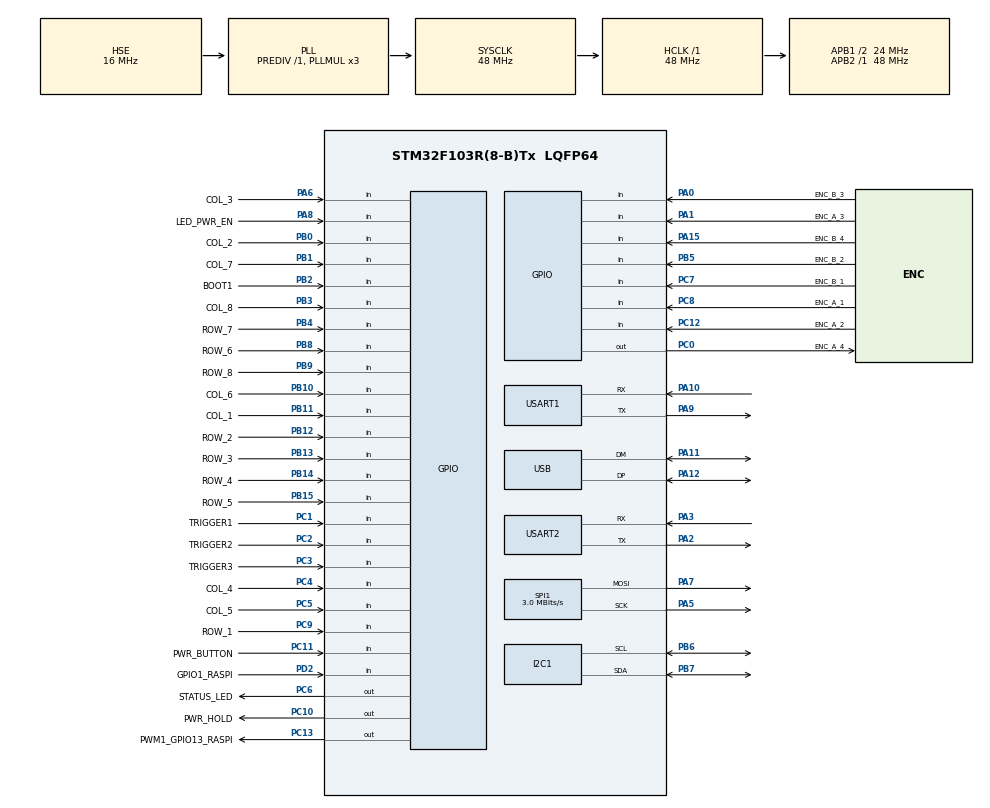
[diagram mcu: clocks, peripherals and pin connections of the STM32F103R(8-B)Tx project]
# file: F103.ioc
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Dma.Request0=SPI1_TX
Dma.SPI1_TX.0.Direction=DMA_MEMORY_TO_PERIPH
Dma.SPI1_TX.0.Instance=DMA1_Channel3
Dma.SPI1_TX.0.MemDataAlignment=DMA_MDATAALIGN_BYTE
Dma.SPI1_TX.0.MemInc=DMA_MINC_ENABLE
Dma.SPI1_TX.0.Mode=DMA_NORMAL
Dma.SPI1_TX.0.PeriphDataAlignment=DMA_PDATAALIGN_BYTE
Dma.SPI1_TX.0.PeriphInc=DMA_PINC_DISABLE
Dma.SPI1_TX.0.Priority=DMA_PRIORITY_LOW
Mcu.Family=STM32F1
Mcu.Name=STM32F103R(8-B)Tx
Mcu.Package=LQFP64
NVIC.DMA1_Channel3_IRQn=true\:0\:0\:false\:false\:true\:false\:true
NVIC.PriorityGroup=NVIC_PRIORITYGROUP_4
PA0-WKUP.GPIO_Label=ENC_B_3
PA0-WKUP.Signal=GPIO_Input
PA1.GPIO_Label=ENC_A_3
PA1.Signal=GPIO_Input
PA10.Mode=Asynchronous
PA10.Signal=USART1_RX
PA11.Mode=Device
PA11.Signal=USB_DM
PA12.Mode=Device
PA12.Signal=USB_DP
PA13.Mode=Serial_Wire
PA13.Signal=SYS_JTMS-SWDIO
PA14.Mode=Serial_Wire
PA14.Signal=SYS_JTCK-SWCLK
PA15.GPIO_Label=ENC_B_4
PA15.Signal=GPIO_Input
PA2.Mode=Asynchronous
PA2.Signal=USART2_TX
PA3.Mode=Asynchronous
PA3.Signal=USART2_RX
PA5.Mode=TX_Only_Simplex_Unidirect_Master
PA5.Signal=SPI1_SCK
PA6.GPIO_Label=COL_3
PA6.Signal=GPIO_Input
PA7.Mode=TX_Only_Simplex_Unidirect_Master
PA7.Signal=SPI1_MOSI
PA8.GPIO_Label=LED_PWR_EN
PA8.Signal=GPIO_Input
PA9.Mode=Asynchronous
PA9.Signal=USART1_TX
PB0.GPIO_Label=COL_2
PB0.Signal=GPIO_Input
PB1.GPIO_Label=COL_7
PB1.Signal=GPIO_Input
PB10.GPIO_Label=COL_6
PB10.Signal=GPIO_Input
PB11.GPIO_Label=COL_1
PB11.Signal=GPIO_Input
PB12.GPIO_Label=ROW_2
PB12.Signal=GPIO_Input
PB13.GPIO_Label=ROW_3
PB13.Signal=GPIO_Input
PB14.GPIO_Label=ROW_4
PB14.Signal=GPIO_Input
PB15.GPIO_Label=ROW_5
PB15.Signal=GPIO_Input
PB2.GPIO_Label=BOOT1
PB2.Signal=GPIO_Input
PB3.GPIO_Label=COL_8
PB3.Signal=GPIO_Input
PB4.GPIO_Label=ROW_7
PB4.Signal=GPIO_Input
PB5.GPIO_Label=ENC_B_2
PB5.Signal=GPIO_Input
PB6.Mode=I2C
PB6.Signal=I2C1_SCL
PB7.Mode=I2C
PB7.Signal=I2C1_SDA
PB8.GPIO_Label=ROW_6
PB8.Signal=GPIO_Input
PB9.GPIO_Label=ROW_8
PB9.Signal=GPIO_Input
PC0.GPIO_Label=ENC_A_4
PC0.Signal=GPIO_Output
PC1.GPIO_Label=TRIGGER1
PC1.Signal=GPIO_Input
PC10.GPIO_Label=PWR_HOLD
PC10.Signal=GPIO_Output
PC11.GPIO_Label=PWR_BUTTON
PC11.Signal=GPIO_Input
PC12.GPIO_Label=ENC_A_2
PC12.Signal=GPIO_Input
PC13-TAMPER-RTC.GPIO_Label=PWM1_GPIO13_RASPI
PC13-TAMPER-RTC.Signal=GPIO_Output
PC14-OSC32_IN.Mode=LSE-External-Oscillator
PC14-OSC32_IN.Signal=RCC_OSC32_IN
PC15-OSC32_OUT.Mode=LSE-External-Oscillator
PC15-OSC32_OUT.Signal=RCC_OSC32_OUT
PC2.GPIO_Label=TRIGGER2
PC2.Signal=GPIO_Input
PC3.GPIO_Label=TRIGGER3
PC3.Signal=GPIO_Input
PC4.GPIO_Label=COL_4
PC4.Signal=GPIO_Input
PC5.GPIO_Label=COL_5
PC5.Signal=GPIO_Input
PC6.GPIO_Label=STATUS_LED
PC6.Signal=GPIO_Output
PC7.GPIO_Label=ENC_B_1
PC7.Signal=GPIO_Input
PC8.GPIO_Label=ENC_A_1
PC8.Signal=GPIO_Input
PC9.GPIO_Label=ROW_1
PC9.Signal=GPIO_Input
PD0-OSC_IN.Mode=HSE-External-Oscillator
PD0-OSC_IN.Signal=RCC_OSC_IN
PD1-OSC_OUT.Mode=HSE-External-Oscillator
PD1-OSC_OUT.Signal=RCC_OSC_OUT
PD2.GPIO_Label=GPIO1_RASPI
PD2.Signal=GPIO_Input
ProjectManager.HeapSize=0x200
ProjectManager.StackSize=0x400
ProjectManager.TargetToolchain=Makefile
RCC.AHBFreq_Value=48000000
RCC.APB1CLKDivider=RCC_HCLK_DIV2
RCC.APB1Freq_Value=24000000
RCC.APB1TimFreq_Value=48000000
RCC.APB2Freq_Value=48000000
RCC.APB2TimFreq_Value=48000000
RCC.HCLKFreq_Value=48000000
RCC.HSE_VALUE=16000000
RCC.PLLMUL=RCC_PLL_MUL3
RCC.PLLSourceVirtual=RCC_PLLSOURCE_HSE
RCC.RTCClockSelection=RCC_RTCCLKSOURCE_LSE
RCC.SYSCLKFreq_VALUE=48000000
RCC.SYSCLKSource=RCC_SYSCLKSOURCE_PLLCLK
RCC.USBFreq_Value=48000000
SPI1.BaudRatePrescaler=SPI_BAUDRATEPRESCALER_16
SPI1.CalculateBaudRate=3.0 MBits/s
SPI1.Direction=SPI_DIRECTION_2LINES
SPI1.Mode=SPI_MODE_MASTER
SPI1.VirtualType=VM_MASTER
USART1.VirtualMode=VM_ASYNC
USART2.VirtualMode=VM_ASYNC
VP_RTC_VS_RTC_Activate.Mode=RTC_Enabled
board=custom

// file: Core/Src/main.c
/* USER CODE BEGIN Header */
/**
  ******************************************************************************
  * @file           : main.c
  * @brief          : Main program body
  ******************************************************************************
  * @attention
  *
  * <h2><center>&copy; Copyright (c) 2021 STMicroelectronics.
  * All rights reserved.</center></h2>
  *
  * This software component is licensed by ST under BSD 3-Clause license,
  * the "License"; You may not use this file except in compliance with the
  * License. You may obtain a copy of the License at:
  *                        opensource.org/licenses/BSD-3-Clause
  *
  ******************************************************************************
  */
/* USER CODE END Header */
#include "main.h"
#include "dma.h"
#include "i2c.h"
#include "rtc.h"
#include "spi.h"
#include "usart.h"
#include "usb.h"
#include "gpio.h"

/* USER CODE BEGIN Includes */
#include "../../Otto/otto.h"
/* USER CODE END Includes */

void SystemClock_Config(void);

int main(void)
{

  /* MCU Configuration--------------------------------------------------------*/

  /* Reset of all peripherals, Initializes the Flash interface and the Systick. */
  HAL_Init();

  /* Configure the system clock */
  SystemClock_Config();

  /* USER CODE BEGIN SysInit */
  OTTO_preinit();
  /* USER CODE END SysInit */

  /* Initialize all configured peripherals */
  MX_GPIO_Init();
  MX_DMA_Init();
  MX_I2C1_Init();
  MX_RTC_Init();
  MX_SPI1_Init();
  MX_USART1_UART_Init();
  MX_USART2_UART_Init();
  MX_USB_PCD_Init();

  /* Infinite loop */

    /* USER CODE BEGIN 3 */
  OTTO_main_loop();
  /* USER CODE END 3 */
}

void SystemClock_Config(void)
{
  RCC_OscInitTypeDef RCC_OscInitStruct = {0};
  RCC_ClkInitTypeDef RCC_ClkInitStruct = {0};
  RCC_PeriphCLKInitTypeDef PeriphClkInit = {0};

  /** Initializes the RCC Oscillators according to the specified parameters
  * in the RCC_OscInitTypeDef structure.
  */
  RCC_OscInitStruct.OscillatorType = RCC_OSCILLATORTYPE_HSE|RCC_OSCILLATORTYPE_LSE;
  RCC_OscInitStruct.HSEState = RCC_HSE_ON;
  RCC_OscInitStruct.HSEPredivValue = RCC_HSE_PREDIV_DIV1;
  RCC_OscInitStruct.LSEState = RCC_LSE_ON;
  RCC_OscInitStruct.HSIState = RCC_HSI_ON;
  RCC_OscInitStruct.PLL.PLLState = RCC_PLL_ON;
  RCC_OscInitStruct.PLL.PLLSource = RCC_PLLSOURCE_HSE;
  RCC_OscInitStruct.PLL.PLLMUL = RCC_PLL_MUL3;
  if (HAL_RCC_OscConfig(&RCC_OscInitStruct) != HAL_OK)
  {
    Error_Handler();
  }
  /** Initializes the CPU, AHB and APB buses clocks
  */
  RCC_ClkInitStruct.ClockType = RCC_CLOCKTYPE_HCLK|RCC_CLOCKTYPE_SYSCLK
                              |RCC_CLOCKTYPE_PCLK1|RCC_CLOCKTYPE_PCLK2;
  RCC_ClkInitStruct.SYSCLKSource = RCC_SYSCLKSOURCE_PLLCLK;
  RCC_ClkInitStruct.AHBCLKDivider = RCC_SYSCLK_DIV1;
  RCC_ClkInitStruct.APB1CLKDivider = RCC_HCLK_DIV2;
  RCC_ClkInitStruct.APB2CLKDivider = RCC_HCLK_DIV1;

  if (HAL_RCC_ClockConfig(&RCC_ClkInitStruct, FLASH_LATENCY_1) != HAL_OK)
  {
    Error_Handler();
  }
  PeriphClkInit.PeriphClockSelection = RCC_PERIPHCLK_RTC|RCC_PERIPHCLK_USB;
  PeriphClkInit.RTCClockSelection = RCC_RTCCLKSOURCE_LSE;
  PeriphClkInit.UsbClockSelection = RCC_USBCLKSOURCE_PLL;
  if (HAL_RCCEx_PeriphCLKConfig(&PeriphClkInit) != HAL_OK)
  {
    Error_Handler();
  }
}

void Error_Handler(void)
{
  /* USER CODE BEGIN Error_Handler_Debug */
  /* User can add his own implementation to report the HAL error return state */
  __disable_irq();
  while (1)
  {
    HAL_GPIO_WritePin(STATUS_LED_GPIO_Port, STATUS_LED_Pin, GPIO_PIN_RESET);
    HAL_Delay(100);
    HAL_GPIO_WritePin(STATUS_LED_GPIO_Port, STATUS_LED_Pin, GPIO_PIN_SET);
    HAL_Delay(100);
  }
  /* USER CODE END Error_Handler_Debug */
}

/************************ (C) COPYRIGHT STMicroelectronics *****END OF FILE****/
